# STM32WL31 register map
File version: 1.1
CPU: CM0+ r0p0, little endian, MPU, no FPU, 4 interrupt priority bits
Registers are 32-bit, read-write, reset 0x0 unless marked. A register's access mark holds for its fields unless they carry their own. Offsets are from the block's base; [hi:lo] are bit positions; {n}, {i} and the like mark numbered series.

## FLASH_CTRL — 4kb addressable space
Base 0x40001000
0x00 COMMAND
  [7:0] COMMAND — Macro commands for flash operations (may require DATA0...DATA3 to be set): - 0x11 : ERASE - 0x22 : MASSERASE - 0x33 : WRITE - 0x55 : MASSREAD - 0xAA : SLEEP - 0xBB : WAKEUP - 0xCC : BURSTWRITE - 0xEE : OTPWRITE - 0xFF : KEYWRITE
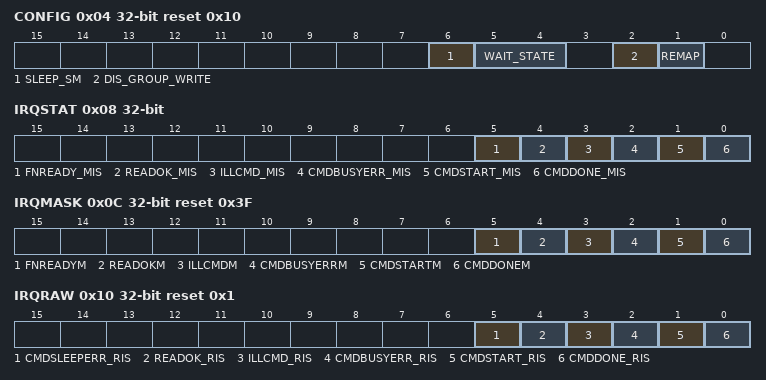
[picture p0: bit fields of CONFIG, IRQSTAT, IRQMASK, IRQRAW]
0x04 CONFIG reset 0x10
  [6] SLEEP_SM — Flash memory power-down mode enable in SLEEP mode This bit allows to have the Flash memory in power-down mode or in idle mode when the device is in Sleep mode. - 0: When the device is in Sleep mode, the NVM is in Idle mode. - 1: When the device is in Sleep mode, the NVM is in power-down mode.
  [5:4] WAIT_STATE — Add latency to flash read opeations: - 00 : no latency - 01 : 1 clock cycle latency - 10 : 2 clock cycles latency - 11 : 3 clock cycles latency
  [2] DIS_GROUP_WRITE — Burst write Control: - 0 : burst write allowed - 1 : burst write forbidden
  [1] REMAP — CPU access routing (it supersedes PREMAP configuration): - 0 : FLASH memory addressed - 1 : SRAM0 memory addressed
0x08 IRQSTAT
  [5] FNREADY_MIS — (1: clear, 0: inactive) FNREADY_MIS flag
  [4] READOK_MIS — (1: clear, 0: inactive) READOK_MIS flag
  [3] ILLCMD_MIS — (1: clear, 0: inactive) ILLCMD_MIS flag
  [2] CMDBUSYERR_MIS — (1: clear, 0: inactive) CMDBUSYERR_MIS flag
  [1] CMDSTART_MIS — (1: clear, 0: inactive) CMDSTART_MIS flag
  [0] CMDDONE_MIS — (1: clear, 0: inactive) CMDDONE_MIS flag
0x0C IRQMASK reset 0x3F
  [5] FNREADYM — (1: mask, 0: inactive) FNREADY_MIS mask
  [4] READOKM — (1: mask, 0: inactive) READOK_MIS mask
  [3] ILLCMDM — (1: mask, 0: inactive) ILLCMD_MIS mask
  [2] CMDBUSYERRM — (1: mask, 0: inactive) CMDBUSYERR_MIS mask
  [1] CMDSTARTM — (1: mask, 0: inactive) CMDSTART_MIS mask
  [0] CMDDONEM — (1: mask, 0: inactive) CMDDONE_MIS mask
0x10 IRQRAW reset 0x1
  [5] CMDSLEEPERR_RIS — (1: active, 0: inactive) COMMAND issued while flash in sleep-mode (SLM=1)
  [4] READOK_RIS — (1: active, 0: inactive) READ COMMAND completed successfully
  [3] ILLCMD_RIS — (1: active, 0: inactive) Illegal command issued
  [2] CMDBUSYERR_RIS — (1: active, 0: inactive) COMMAND issued while flash busy
  [1] CMDSTART_RIS — (1: active, 0: inactive) COMMAND sequence started
  [0] CMDDONE_RIS — (1: active, 0: inactive) COMMAND sequence ended
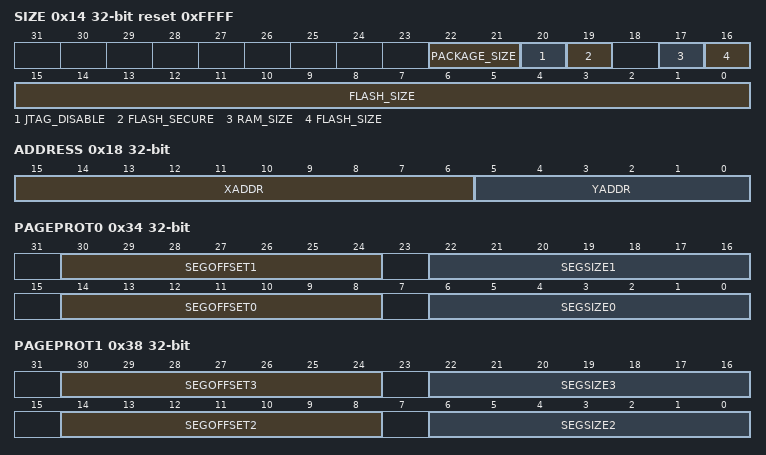
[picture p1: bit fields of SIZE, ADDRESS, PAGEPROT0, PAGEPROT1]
0x14 SIZE ro reset 0xFFFF
  [22:21] PACKAGE_SIZE — Package selection: - 0- : CSP - 10 : 32pins - 11 : 48pins
  [20] JTAG_DISABLE — Flash+JTAG protection (0: no JTAG protection - see FLASH_SECURE, 1: Flash and JTAG protected)
  [19] FLASH_SECURE — Flash memory protection (0: no key present, 1: key present)
  [17] RAM_SIZE — RAM memory size selection: - 0 : 16kb - 1 : 32kb
  [16:0] FLASH_SIZE — Maximum valid address for flash memory: - 00 : 0x03FFF (64kb) - 01 : 0x07FFF (128kb) - 10 : 0x0BFFF (192kb) - 11 : 0x0FFFF (256kb)
0x18 ADDRESS
  [15:6] XADDR — Flash row address offset to be used with some COMMAND
  [5:0] YADDR — Flash column address offset to be used with some COMMAND
0x24 LFSRVAL ro reset 0xFFFFFFFF
  [31:0] LFSRVAL — Flash read data CRC signature
0x34 PAGEPROT0
  [30:24] SEGOFFSET1 — Second segment, 7-bit page protection offset (first page number in protected segment)
  [22:16] SEGSIZE1 — Second segment, 7-bit page protection size (number of pages to protect in segment, first page included)
  [14:8] SEGOFFSET0 — First segment, 7-bit page protection offset (first page number in protected segment)
  [6:0] SEGSIZE0 — First segment, 7-bit page protection size (number of pages to protect in segment, first page included)
0x38 PAGEPROT1
  [30:24] SEGOFFSET3 — Fourth segment, 7-bit page protection offset (first page number in protected segment)
  [22:16] SEGSIZE3 — Fourth segment, 7-bit page protection size (number of pages to protect in segment, first page included)
  [14:8] SEGOFFSET2 — Third segment, 7-bit page protection offset (first page number in protected segment)
  [6:0] SEGSIZE2 — Third segment, 7-bit page protection size (number of pages to protect in segment, first page included)
0x40 DATA0 reset 0xFFFFFFFF
  [31:0] DATA0 — Value to be used as DATA for any COMMAND of type WRITE and compare value for MASSREAD
{0x40+4i} DATA{i} reset 0xFFFFFFFF (i=1..3)
  [31:0] DATA{i} — Value to be used as DATA for any COMMAND of type WRITE
0x50 UNLOCK012 reset 0xFFFFFFFF
  [31:0] UNLOCK012 — (NOT TO BE DOCUMENTED) Remove read-write protection from IFR0, IFR1, IFR2 sectors
0x54 UNLOCK3 reset 0xFFFFFFFF
  [31:0] UNLOCK3 — (NOT TO BE DOCUMENTED) Remove read-write protection from IFR3 sector

## Notices in the file
Copyright (c) 2025 STMicroelectronics.
SPDX-License-Identifier: Apache-2.0
Licensed under the Apache License, Version 2.0 (the "License");
you may not use this file except in compliance with the License.
You may obtain a copy of the License at
http://www.apache.org/licenses/LICENSE-2.0
Unless required by applicable law or agreed to in writing, software
distributed under the License is distributed on an "AS IS" BASIS,
WITHOUT WARRANTIES OR CONDITIONS OF ANY KIND, either express or implied.
See the License for the specific language governing permissions and
limitations under the License.
